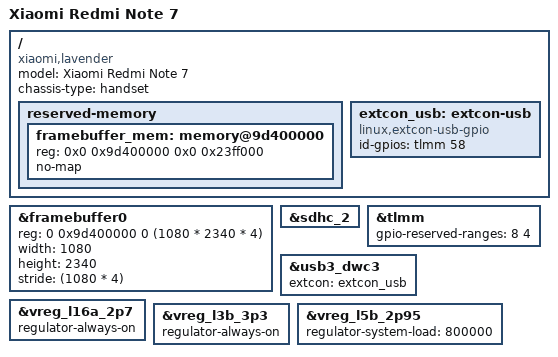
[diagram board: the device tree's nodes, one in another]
// SPDX-License-Identifier: GPL-2.0-only
/*
 * Copyright (c) 2020, Alexey Minnekhanov <alexeymin@minlexx.ru>
 * Copyright (c) 2021, Dang Huynh <danct12@riseup.net>
 */

/dts-v1/;

#include "sdm660.dtsi"
#include "sdm660-xiaomi-common.dtsi"

/ {
	model = "Xiaomi Redmi Note 7";
	compatible = "xiaomi,lavender", "qcom,sdm660";
	chassis-type = "handset";

	reserved-memory {
		/* Override framebuffer memory size for lavender's 2340px display */
		framebuffer_mem: memory@9d400000 {
			reg = <0x0 0x9d400000 0x0 0x23ff000>;
			no-map;
		};
	};

	extcon_usb: extcon-usb {
		compatible = "linux,extcon-usb-gpio";
		id-gpios = <&tlmm 58 GPIO_ACTIVE_HIGH>;
	};
};

&framebuffer0 {
	reg = <0 0x9d400000 0 (1080 * 2340 * 4)>;
	width = <1080>;
	height = <2340>;
	stride = <(1080 * 4)>;

};

&sdhc_2 {
	status = "okay";
};

&tlmm {
	gpio-reserved-ranges = <8 4>; /* Fingerprint SPI */
};

&usb3_dwc3 {
	extcon = <&extcon_usb>;
};

&vreg_l16a_2p7 {
	regulator-always-on;
};

&vreg_l3b_3p3 {
	/* Keep the proximity-sensor and bottom-board supply enabled. */
	regulator-always-on;
};

&vreg_l5b_2p95 {
	regulator-system-load = <800000>;
};
